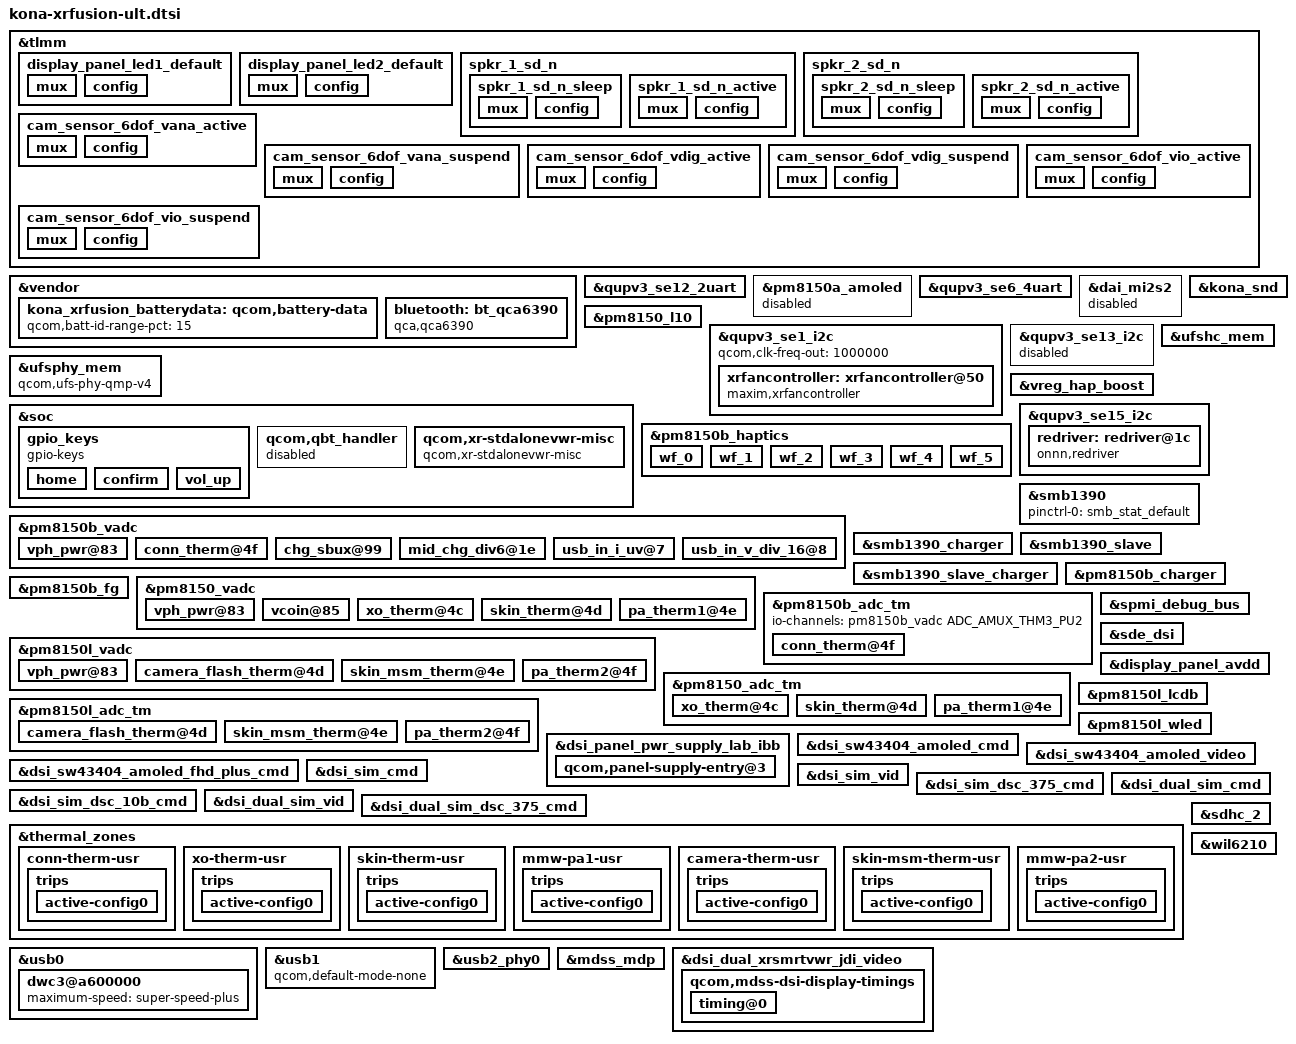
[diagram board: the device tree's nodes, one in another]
#include <dt-bindings/gpio/gpio.h>
#include "kona-pmic-overlay.dtsi"
#include "kona-sde-display.dtsi"
#include "kona-audio-overlay.dtsi"
#include "kona-thermal-overlay.dtsi"
#include "kona-xr-pinctrl-overlay.dtsi"
//#include "camera/kona-camera-sensor-xrfusion.dtsi"

&tlmm {
	display_panel_led1_default: display_panel_led1_default {
		mux {
			pins = "gpio144";
			function = "gpio";
		};

		config {
			pins = "gpio144";
			drive-strength = <8>;
			bias-disable = <0>;
			output-high;
		};
	};

	display_panel_led2_default: display_panel_led2_default {
		mux {
			pins = "gpio140";
			function = "gpio";
		};

		config {
			pins = "gpio140";
			drive-strength = <8>;
			bias-disable = <0>;
			output-high;
		};
	};

	spkr_1_sd_n {
		spkr_1_sd_n_sleep: spkr_1_sd_n_sleep {
			mux {
				pins = "gpio127";
				function = "gpio";
			};

			config {
				pins = "gpio127";
				drive-strength = <2>;   /* 2 mA */
				bias-pull-down;
				input-enable;
			};
		};

		spkr_1_sd_n_active: spkr_1_sd_n_active {
			mux {
				pins = "gpio127";
				function = "gpio";
			};

			config {
				pins = "gpio127";
				drive-strength = <16>;   /* 16 mA */
				bias-disable;
				output-high;
			};
		};
	};

	spkr_2_sd_n {
		spkr_2_sd_n_sleep: spkr_2_sd_n_sleep {
			mux {
				pins = "gpio129";
				function = "gpio";
			};

			config {
				pins = "gpio129";
				drive-strength = <2>;   /* 2 mA */
				bias-pull-down;
				input-enable;
			};
		};

		spkr_2_sd_n_active: spkr_2_sd_n_active {
			mux {
				pins = "gpio129";
				function = "gpio";
			};

			config {
				pins = "gpio129";
				drive-strength = <16>;   /* 16 mA */
				bias-disable;
				output-high;
			};
		};
	};

	cam_sensor_6dof_vana_active: cam_sensor_6dof_vana_active {
		/*  AVDD LDO */
		mux {
			pins = "gpio43";
			function = "gpio";
		};

		config {
			pins = "gpio43";
			bias-disable; /* No PULL */
			drive-strength = <2>; /* 2 MA */
		};
	};

	cam_sensor_6dof_vana_suspend: cam_sensor_6dof_vana_suspend {
		/*  AVDD LDO */
		mux {
			pins = "gpio43";
			function = "gpio";
		};

		config {
			pins = "gpio43";
			bias-pull-down; /* PULL DOWN */
			drive-strength = <2>; /* 2 MA */
		};
	};

	cam_sensor_6dof_vdig_active: cam_sensor_6dof_vdig_active {
		/*  VDIG LDO */
		mux {
			pins = "gpio42";
			function = "gpio";
		};

		config {
			pins = "gpio42";
			bias-disable; /* No PULL */
			drive-strength = <2>; /* 2 MA */
		};
	};

	cam_sensor_6dof_vdig_suspend: cam_sensor_6dof_vdig_suspend {
		/*  VDIG LDO */
		mux {
			pins = "gpio42";
			function = "gpio";
		};

		config {
			pins = "gpio42";
			bias-pull-down; /* PULL DOWN */
			drive-strength = <2>; /* 2 MA */
		};
	};

	cam_sensor_6dof_vio_active: cam_sensor_6dof_vio_active {
		/*  VIO LDO */
		mux {
			pins = "gpio41";
			function = "gpio";
		};

		config {
			pins = "gpio41";
			bias-disable; /* No PULL */
			drive-strength = <2>; /* 2 MA */
		};
	};

	cam_sensor_6dof_vio_suspend: cam_sensor_6dof_vio_suspend {
		/*  VIO LDO */
		mux {
			pins = "gpio41";
			function = "gpio";
		};

		config {
			pins = "gpio41";
			bias-pull-down; /* PULL DOWN */
			drive-strength = <2>; /* 2 MA */
		};
	};
};

&vendor {
	kona_xrfusion_batterydata: qcom,battery-data {
		qcom,batt-id-range-pct = <15>;
		#include "fg-gen4-batterydata-goertek-6100mah.dtsi"
	};
};

&qupv3_se12_2uart {
	status = "okay";
};

&pm8150a_amoled {
	status = "disabled";
};

&qupv3_se6_4uart {
	status = "ok";
};

&dai_mi2s2 {
	status = "disabled";
	qcom,msm-mi2s-tx-lines = <1>;
	pinctrl-names = "default", "sleep";
	pinctrl-0 = <&tert_mi2s_sck_active &tert_mi2s_ws_active
			&tert_mi2s_sd0_active>;
	pinctrl-1 = <&tert_mi2s_sck_sleep &tert_mi2s_ws_sleep
			&tert_mi2s_sd0_sleep>;
};

&kona_snd {
	qcom,model = "kona-xrfusion-ult-snd-card";
	qcom,mi2s-audio-intf = <0>;
	qcom,audio-routing =
		"AMIC1", "MIC BIAS1",
		"MIC BIAS1", "Analog Mic1",
		"AMIC2", "MIC BIAS2",
		"MIC BIAS2", "Analog Mic2",
		"AMIC3", "MIC BIAS3",
		"MIC BIAS3", "Analog Mic3",
		"AMIC4", "MIC BIAS4",
		"MIC BIAS4", "Analog Mic4",
		"AMIC5", "MIC BIAS5",
		"MIC BIAS5", "Analog Mic5",
		"AMIC6", "MIC BIAS6",
		"MIC BIAS6", "Analog Mic6",
		"DMIC0", "MIC BIAS1",
		"MIC BIAS1", "Digital Mic0",
		"DMIC1", "MIC BIAS1",
		"MIC BIAS1", "Digital Mic1",
		"DMIC2", "MIC BIAS1",
		"MIC BIAS1", "Digital Mic2",
		"DMIC3", "MIC BIAS1",
		"MIC BIAS1", "Digital Mic3",
		"DMIC4", "MIC BIAS3",
		"MIC BIAS3", "Digital Mic4",
		"DMIC5", "MIC BIAS4",
		"MIC BIAS4", "Digital Mic5",
		"DMIC6", "MIC BIAS3",
		"MIC BIAS3", "Digital Mic6",
		"DMIC7", "MIC BIAS3",
		"MIC BIAS3", "Digital Mic7",
		"IN1_HPHL", "HPHL_OUT",
		"IN2_HPHR", "HPHR_OUT",
		"IN3_AUX", "AUX_OUT",
		"TX SWR_ADC0", "ADC1_OUTPUT",
		"TX SWR_ADC1", "ADC2_OUTPUT",
		"TX SWR_ADC2", "ADC3_OUTPUT",
		"TX SWR_ADC3", "ADC4_OUTPUT",
		"TX SWR_DMIC0", "DMIC1_OUTPUT",
		"TX SWR_DMIC1", "DMIC2_OUTPUT",
		"TX SWR_DMIC2", "DMIC3_OUTPUT",
		"TX SWR_DMIC3", "DMIC4_OUTPUT",
		"TX SWR_DMIC4", "DMIC5_OUTPUT",
		"TX SWR_DMIC5", "DMIC6_OUTPUT",
		"TX SWR_DMIC6", "DMIC7_OUTPUT",
		"TX SWR_DMIC7", "DMIC8_OUTPUT",
		"WSA SRC0_INP", "SRC0",
		"WSA_TX DEC0_INP", "TX DEC0 MUX",
		"WSA_TX DEC1_INP", "TX DEC1 MUX",
		"RX_TX DEC0_INP", "TX DEC0 MUX",
		"RX_TX DEC1_INP", "TX DEC1 MUX",
		"RX_TX DEC2_INP", "TX DEC2 MUX",
		"RX_TX DEC3_INP", "TX DEC3 MUX",
		"SpkrRight IN", "WSA_SPK2 OUT",
		"VA_AIF1 CAP", "VA_SWR_CLK",
		"VA_AIF2 CAP", "VA_SWR_CLK",
		"VA_AIF3 CAP", "VA_SWR_CLK",
		"VA MIC BIAS3", "Digital Mic0",
		"VA MIC BIAS3", "Digital Mic1",
		"VA MIC BIAS1", "Digital Mic2",
		"VA MIC BIAS1", "Digital Mic3",
		"VA MIC BIAS4", "Digital Mic5",
		"VA DMIC0", "VA MIC BIAS3",
		"VA DMIC1", "VA MIC BIAS3",
		"VA DMIC2", "VA MIC BIAS1",
		"VA DMIC3", "VA MIC BIAS1",
		"VA DMIC5", "VA MIC BIAS4",
		"VA SWR_ADC1", "VA_SWR_CLK",
		"VA SWR_MIC0", "VA_SWR_CLK",
		"VA SWR_MIC1", "VA_SWR_CLK",
		"VA SWR_MIC2", "VA_SWR_CLK",
		"VA SWR_MIC3", "VA_SWR_CLK",
		"VA SWR_MIC4", "VA_SWR_CLK",
		"VA SWR_MIC5", "VA_SWR_CLK",
		"VA SWR_MIC6", "VA_SWR_CLK",
		"VA SWR_MIC7", "VA_SWR_CLK",
		"VA SWR_MIC0", "DMIC1_OUTPUT",
		"VA SWR_MIC1", "DMIC2_OUTPUT",
		"VA SWR_MIC2", "DMIC3_OUTPUT",
		"VA SWR_MIC3", "DMIC4_OUTPUT",
		"VA SWR_MIC4", "DMIC5_OUTPUT",
		"VA SWR_MIC5", "DMIC6_OUTPUT",
		"VA SWR_MIC6", "DMIC7_OUTPUT",
		"VA SWR_MIC7", "DMIC8_OUTPUT",
		"VA SWR_ADC1", "ADC2_OUTPUT";
		qcom,msm-mbhc-hphl-swh = <1>;
		qcom,msm-mbhc-gnd-swh = <1>;
		qcom,cdc-dmic01-gpios = <&cdc_dmic01_gpios>;
		qcom,cdc-dmic23-gpios = <&cdc_dmic23_gpios>;
		qcom,cdc-dmic45-gpios = <&cdc_dmic45_gpios>;
		asoc-codec  = <&stub_codec>, <&bolero>, <&ext_disp_audio_codec>;
		asoc-codec-names = "msm-stub-codec.1", "bolero_codec",
				"msm-ext-disp-audio-codec-rx";
		qcom,wsa-max-devs = <2>;
		qcom,wsa-devs = <&wsa881x_0211>, <&wsa881x_0212>,
		<&wsa881x_0213>, <&wsa881x_0214>;
		qcom,wsa-aux-dev-prefix = "SpkrLeft", "SpkrRight",
		"SpkrLeft", "SpkrRight";
		qcom,codec-max-aux-devs = <1>;
		qcom,codec-aux-devs = <&wcd938x_codec>;
		qcom,msm_audio_ssr_devs = <&audio_apr>, <&q6core>, <&lpi_tlmm>,
				<&bolero>;
};

&pm8150_l10 {
	regulator-max-microvolt = <3304000>;
	qcom,init-voltage = <3304000>;
};

&qupv3_se1_i2c {
	status = "ok";
	qcom,clk-freq-out = <1000000>;
	#address-cells = <1>;
	#size-cells = <0>;
	xrfancontroller: xrfancontroller@50 {
		compatible = "maxim,xrfancontroller";
		reg = <0x50>;
		qcom,fan-pwr-en = <&tlmm 38 0x00>;
		qcom,fan-pwr-bp = <&tlmm 39 0x00>;
	};
};

&qupv3_se13_i2c {
	#address-cells = <1>;
	#size-cells = <0>;

	status = "disabled";
};

&ufsphy_mem {
	compatible = "qcom,ufs-phy-qmp-v4";

	vdda-phy-supply = <&pm8150_l5>;
	vdda-phy-always-on;
	vdda-pll-supply = <&pm8150_l9>;
	vdda-phy-max-microamp = <89900>;
	vdda-pll-max-microamp = <18800>;

	status = "ok";
};

&ufshc_mem {
	vdd-hba-supply = <&ufs_phy_gdsc>;
	vdd-hba-fixed-regulator;
	vcc-supply = <&pm8150_l17>;
	vcc-voltage-level = <2504000 2950000>;
	vcc-low-voltage-sup;
	vccq-supply = <&pm8150_l6>;
	vccq2-supply = <&pm8150_s4>;
	vcc-max-microamp = <800000>;
	vccq-max-microamp = <800000>;
	vccq2-max-microamp = <800000>;

	qcom,vddp-ref-clk-supply = <&pm8150_l6>;
	qcom,vddp-ref-clk-max-microamp = <100>;
	qcom,vccq-parent-supply = <&pm8150a_s8>;
	qcom,vccq-parent-max-microamp = <210000>;

	status = "ok";
};

&soc {
	gpio_keys {
		compatible = "gpio-keys";
		label = "gpio-keys";

		pinctrl-names = "default";
		pinctrl-0 = <&key_vol_up_default
				&key_confirm_default
				&key_vol_up_default>;

		home {
			label = "home";
			gpios = <&pm8150_gpios 1 GPIO_ACTIVE_LOW>;
			linux,input-type = <1>;
			linux,code = <KEY_BACK>;
			gpio-key,wakeup;
			debounce-interval = <15>;
			linux,can-disable;
		};

		confirm {
			label = "confirm";
			gpios = <&pm8150_gpios 7 GPIO_ACTIVE_LOW>;
			linux,input-type = <1>;
			linux,code = <KEY_ENTER>;
			gpio-key,wakeup;
			debounce-interval = <15>;
			linux,can-disable;
		};

		vol_up {
			label = "volume_up";
			gpios = <&pm8150_gpios 6 GPIO_ACTIVE_LOW>;
			linux,input-type = <1>;
			linux,code = <KEY_VOLUMEUP>;
			gpio-key,wakeup;
			debounce-interval = <15>;
			linux,can-disable;
		};
	};

	qcom,qbt_handler {
		status = "disabled";
	};

	qcom,xr-stdalonevwr-misc {
		compatible = "qcom,xr-stdalonevwr-misc";
		/* IMU CLK Enable PM8150 GPIO 3 */
		pinctrl-names = "default", "sleep";
		pinctrl-0 = <&imu_clkin_default>;
		pinctrl-1 = <&imu_clkin_sleep>;
	};
};

&vreg_hap_boost {
	status = "ok";
};

&pm8150b_haptics {
	qcom,vmax-mv = <1697>;
	qcom,play-rate-us = <5882>;
	vdd-supply = <&vreg_hap_boost>;

	wf_0 {
		/* CLICK */
		qcom,wf-play-rate-us = <5882>;
		qcom,wf-vmax-mv = <1697>;
	};

	wf_1 {
		/* DOUBLE CLICK */
		qcom,wf-play-rate-us = <5882>;
		qcom,wf-vmax-mv = <1697>;
	};

	wf_2 {
		/* TICK */
		qcom,wf-play-rate-us = <5882>;
		qcom,wf-vmax-mv = <1697>;
	};

	wf_3 {
		/* THUD */
		qcom,wf-play-rate-us = <5882>;
		qcom,wf-vmax-mv = <1697>;
	};

	wf_4 {
		/* POP */
		qcom,wf-play-rate-us = <5882>;
		qcom,wf-vmax-mv = <1697>;
	};

	wf_5 {
		/* HEAVY CLICK */
		qcom,wf-play-rate-us = <5882>;
		qcom,wf-vmax-mv = <1697>;
	};
};

&pm8150b_vadc {
	#address-cells = <1>;
	#size-cells = <0>;

	vph_pwr@83 {
		reg = <ADC_VPH_PWR>;
		label = "vph_pwr";
		qcom,pre-scaling = <1 3>;
	};

	conn_therm@4f {
		reg = <ADC_AMUX_THM3_PU2>;
		label = "conn_therm";
		qcom,ratiometric;
		qcom,hw-settle-time = <200>;
		qcom,pre-scaling = <1 1>;
	};

	chg_sbux@99 {
		reg = <ADC_SBUx>;
		label = "chg_sbux";
		qcom,pre-scaling = <1 3>;
	};

	mid_chg_div6@1e {
		reg = <ADC_MID_CHG_DIV6>;
		label = "chg_mid";
		qcom,pre-scaling = <1 6>;
	};

	usb_in_i_uv@7 {
		reg = <ADC_USB_IN_I>;
		label = "usb_in_i_uv";
		qcom,pre-scaling = <1 1>;
	};

	usb_in_v_div_16@8 {
		reg = <ADC_USB_IN_V_16>;
		label = "usb_in_v_div_16";
		qcom,pre-scaling = <1 16>;
	};
};

&qupv3_se15_i2c {
	#address-cells = <1>;
	#size-cells = <0>;
	status = "ok";
	redriver: redriver@1c {
		compatible = "onnn,redriver";
		reg = <0x1c>;
		extcon = <&pm8150b_pdphy>, <&pm8150b_pdphy>;
		eq = /bits/ 8 <
				/* Parameters for USB */
				0x4 0x4 0x4 0x4
				/* Parameters for DP */
				0x6 0x4 0x4 0x6>;
		flat-gain = /bits/ 8 <
				/* Parameters for USB */
				0x3 0x1 0x1 0x3
				/* Parameters for DP */
				0x2 0x1 0x1 0x2>;
		output-comp = /bits/ 8 <
				/* Parameters for USB */
				0x3 0x3 0x3 0x3
				/* Parameters for DP */
				0x3 0x3 0x3 0x3>;
		loss-match = /bits/ 8 <
				/* Parameters for USB */
				0x1 0x3 0x3 0x1
				/* Parameters for DP */
				0x3 0x3 0x3 0x3>;
	};

	#include "smb1390.dtsi"
};

&smb1390 {
	pinctrl-names = "default";
	pinctrl-0 = <&smb_stat_default>;
	status = "ok";
};

&smb1390_charger {
	io-channels = <&pm8150b_vadc ADC_AMUX_THM2>;
	io-channel-names = "cp_die_temp";
	qcom,parallel-output-mode = <2>;
	status = "ok";
};

&smb1390_slave {
	status = "ok";
};

&smb1390_slave_charger {
	status = "ok";
};

&pm8150b_charger {
	status = "ok";
	qcom,sec-charger-config = <1>;
	qcom,auto-recharge-soc = <98>;
	io-channels = <&pm8150b_vadc ADC_MID_CHG_DIV6>,
		      <&pm8150b_vadc ADC_USB_IN_I>,
		      <&pm8150b_vadc ADC_SBUx>,
		      <&pm8150b_vadc ADC_VPH_PWR>,
		      <&pm8150b_vadc ADC_CHG_TEMP>;
	io-channel-names = "mid_voltage",
			   "usb_in_current",
			   "sbux_res",
			   "vph_voltage",
			   "chg_temp";
	qcom,battery-data = <&kona_xrfusion_batterydata>;
	qcom,sw-jeita-enable;
	qcom,wd-bark-time-secs = <16>;
	qcom,suspend-input-on-debug-batt;
	qcom,thermal-mitigation = <5325000 4500000 4000000 3500000 3000000
				2500000 2000000 1500000 1000000 500000>;
};

&pm8150b_fg {
	status = "ok";
	qcom,battery-data = <&kona_xrfusion_batterydata>;
	qcom,hold-soc-while-full;
	qcom,linearize-soc;
	qcom,five-pin-battery;
	qcom,cl-wt-enable;
	qcom,soc-scale-mode-en;
	/* ESR fast calibration */
	qcom,fg-esr-timer-chg-fast = <0 7>;
	qcom,fg-esr-timer-dischg-fast = <0 7>;
	qcom,fg-esr-timer-chg-slow = <0 96>;
	qcom,fg-esr-timer-dischg-slow = <0 96>;
	qcom,fg-esr-cal-soc-thresh = <26 230>;
	qcom,fg-esr-cal-temp-thresh = <10 40>;
};

&pm8150_vadc {
	#address-cells = <1>;
	#size-cells = <0>;

	vph_pwr@83 {
		reg = <ADC_VPH_PWR>;
		label = "vph_pwr";
		qcom,pre-scaling = <1 3>;
	};

	vcoin@85 {
		reg = <ADC_VCOIN>;
		label = "vcoin";
		qcom,pre-scaling = <1 3>;
	};

	xo_therm@4c {
		reg = <ADC_XO_THERM_PU2>;
		label = "xo_therm";
		qcom,ratiometric;
		qcom,hw-settle-time = <200>;
		qcom,pre-scaling = <1 1>;
	};

	skin_therm@4d {
		reg = <ADC_AMUX_THM1_PU2>;
		label = "skin_therm";
		qcom,ratiometric;
		qcom,hw-settle-time = <200>;
		qcom,pre-scaling = <1 1>;
	};

	pa_therm1@4e {
		reg = <ADC_AMUX_THM2_PU2>;
		label = "pa_therm1";
		qcom,ratiometric;
		qcom,hw-settle-time = <200>;
		qcom,pre-scaling = <1 1>;
	};
};

&pm8150l_vadc {
	#address-cells = <1>;
	#size-cells = <0>;

	vph_pwr@83 {
		reg = <ADC_VPH_PWR>;
		label = "vph_pwr";
		qcom,pre-scaling = <1 3>;
	};

	camera_flash_therm@4d {
		reg = <ADC_AMUX_THM1_PU2>;
		label = "camera_flash_therm";
		qcom,ratiometric;
		qcom,hw-settle-time = <200>;
		qcom,pre-scaling = <1 1>;
	};

	skin_msm_therm@4e {
		reg = <ADC_AMUX_THM2_PU2>;
		label = "skin_msm_therm";
		qcom,ratiometric;
		qcom,hw-settle-time = <200>;
		qcom,pre-scaling = <1 1>;
	};

	pa_therm2@4f {
		reg = <ADC_AMUX_THM3_PU2>;
		label = "pa_therm2";
		qcom,ratiometric;
		qcom,hw-settle-time = <200>;
		qcom,pre-scaling = <1 1>;
	};
};

&pm8150b_adc_tm {
	#address-cells = <1>;
	#size-cells = <0>;

	io-channels = <&pm8150b_vadc ADC_AMUX_THM3_PU2>;

	conn_therm@4f {
		reg = <ADC_AMUX_THM3_PU2>;
		qcom,ratiometric;
		qcom,hw-settle-time = <200>;
	};
};

&pm8150_adc_tm {
	#address-cells = <1>;
	#size-cells = <0>;

	io-channels = <&pm8150_vadc ADC_XO_THERM_PU2>,
			<&pm8150_vadc ADC_AMUX_THM1_PU2>,
			<&pm8150_vadc ADC_AMUX_THM2_PU2>;

	xo_therm@4c {
		reg = <ADC_XO_THERM_PU2>;
		qcom,ratiometric;
		qcom,hw-settle-time = <200>;
	};

	skin_therm@4d {
		reg = <ADC_AMUX_THM1_PU2>;
		qcom,ratiometric;
		qcom,hw-settle-time = <200>;
	};

	pa_therm1@4e {
		reg = <ADC_AMUX_THM2_PU2>;
		qcom,ratiometric;
		qcom,hw-settle-time = <200>;
	};
};

&pm8150l_adc_tm {
	#address-cells = <1>;
	#size-cells = <0>;

	camera_flash_therm@4d {
		reg = <ADC_AMUX_THM1_PU2>;
		qcom,ratiometric;
		qcom,hw-settle-time = <200>;
	};

	skin_msm_therm@4e {
		reg = <ADC_AMUX_THM2_PU2>;
		qcom,ratiometric;
		qcom,hw-settle-time = <200>;
	};

	pa_therm2@4f {
		reg = <ADC_AMUX_THM3_PU2>;
		qcom,ratiometric;
		qcom,hw-settle-time = <200>;
	};
};

&spmi_debug_bus {
	status = "ok";
};

&sde_dsi {
	avdd-supply = <&display_panel_avdd>;
	lab-supply = <&lcdb_ldo_vreg>;
	ibb-supply = <&lcdb_ncp_vreg>;
	qcom,dsi-default-panel = <&dsi_dual_xrsmrtvwr_jdi_video>;
};

&display_panel_avdd {
	display_panel_led1_gpio = <&tlmm 144 0>;
	display_panel_led2_gpio = <&tlmm 140 0>;
	enable-active-high;
	regulator-boot-on;
	pinctrl-names = "default";
	pinctrl-0 = <&display_panel_led1_default
	&display_panel_led2_default>;
};

&dsi_panel_pwr_supply_lab_ibb {
	qcom,panel-supply-entry@3 {
		reg = <1>;
		qcom,supply-name = "avdd";
		qcom,supply-min-voltage = <4600000>;
		qcom,supply-max-voltage = <6000000>;
		qcom,supply-enable-load = <100000>;
		qcom,supply-disable-load = <100>;
	};
};

&pm8150l_lcdb {
	status = "ok";
};

&pm8150l_wled {
	status = "ok";
};

&dsi_sw43404_amoled_cmd {
	qcom,panel-supply-entries = <&dsi_panel_pwr_supply>;
	qcom,mdss-dsi-bl-pmic-control-type = "bl_ctrl_dcs";
	qcom,mdss-dsi-bl-min-level = <1>;
	qcom,mdss-dsi-bl-max-level = <1023>;
	qcom,mdss-brightness-max-level = <255>;
	qcom,platform-te-gpio = <&tlmm 66 0>;
	qcom,platform-reset-gpio = <&tlmm 75 0>;
	qcom,mdss-dsi-panel-test-pin = <&tlmm 46 0>;
};

&dsi_sw43404_amoled_video {
	qcom,panel-supply-entries = <&dsi_panel_pwr_supply>;
	qcom,mdss-dsi-bl-pmic-control-type = "bl_ctrl_dcs";
	qcom,mdss-dsi-bl-min-level = <1>;
	qcom,mdss-dsi-bl-max-level = <1023>;
	qcom,mdss-brightness-max-level = <255>;
	qcom,platform-reset-gpio = <&tlmm 75 0>;
	qcom,mdss-dsi-panel-test-pin = <&tlmm 46 0>;
};

&dsi_sw43404_amoled_fhd_plus_cmd {
	qcom,panel-supply-entries = <&dsi_panel_pwr_supply>;
	qcom,mdss-dsi-bl-pmic-control-type = "bl_ctrl_dcs";
	qcom,mdss-dsi-bl-min-level = <1>;
	qcom,mdss-dsi-bl-max-level = <1023>;
	qcom,mdss-brightness-max-level = <255>;
	qcom,platform-te-gpio = <&tlmm 66 0>;
	qcom,platform-reset-gpio = <&tlmm 75 0>;
	qcom,mdss-dsi-panel-test-pin = <&tlmm 46 0>;
};

&dsi_sim_cmd {
	qcom,panel-supply-entries = <&dsi_panel_pwr_supply>;
	qcom,mdss-dsi-bl-pmic-control-type = "bl_ctrl_dcs";
	qcom,platform-reset-gpio = <&tlmm 75 0>;
};

&dsi_sim_vid {
	qcom,panel-supply-entries = <&dsi_panel_pwr_supply>;
	qcom,mdss-dsi-bl-pmic-control-type = "bl_ctrl_dcs";
	qcom,platform-reset-gpio = <&tlmm 75 0>;
};

&dsi_sim_dsc_375_cmd {
	qcom,panel-supply-entries = <&dsi_panel_pwr_supply>;
	qcom,mdss-dsi-bl-pmic-control-type = "bl_ctrl_dcs";
	qcom,platform-reset-gpio = <&tlmm 75 0>;
};

&dsi_sim_dsc_10b_cmd {
	qcom,panel-supply-entries = <&dsi_panel_pwr_supply>;
	qcom,mdss-dsi-bl-pmic-control-type = "bl_ctrl_dcs";
	qcom,platform-reset-gpio = <&tlmm 75 0>;
};

&dsi_dual_sim_cmd {
	qcom,panel-supply-entries = <&dsi_panel_pwr_supply>;
	qcom,mdss-dsi-bl-pmic-control-type = "bl_ctrl_dcs";
	qcom,platform-reset-gpio = <&tlmm 75 0>;
};

&dsi_dual_sim_vid {
	qcom,panel-supply-entries = <&dsi_panel_pwr_supply>;
	qcom,mdss-dsi-bl-pmic-control-type = "bl_ctrl_dcs";
	qcom,platform-reset-gpio = <&tlmm 75 0>;
};

&dsi_dual_sim_dsc_375_cmd {
	qcom,panel-supply-entries = <&dsi_panel_pwr_supply>;
	qcom,mdss-dsi-bl-pmic-control-type = "bl_ctrl_dcs";
	qcom,platform-reset-gpio = <&tlmm 75 0>;
};

&thermal_zones {
	conn-therm-usr {
		polling-delay-passive = <0>;
		polling-delay = <0>;
		thermal-governor = "user_space";
		thermal-sensors = <&pm8150b_adc_tm ADC_AMUX_THM3_PU2>;
		trips {
			active-config0 {
				temperature = <125000>;
				hysteresis = <1000>;
				type = "passive";
			};
		};
	};

	xo-therm-usr {
		polling-delay-passive = <0>;
		polling-delay = <0>;
		thermal-governor = "user_space";
		thermal-sensors = <&pm8150_adc_tm ADC_XO_THERM_PU2>;
		trips {
			active-config0 {
				temperature = <125000>;
				hysteresis = <1000>;
				type = "passive";
			};
		};
	};

	skin-therm-usr {
		polling-delay-passive = <0>;
		polling-delay = <0>;
		thermal-governor = "user_space";
		thermal-sensors = <&pm8150_adc_tm ADC_AMUX_THM1_PU2>;
		trips {
			active-config0 {
				temperature = <125000>;
				hysteresis = <1000>;
				type = "passive";
			};
		};
	};

	mmw-pa1-usr {
		polling-delay-passive = <0>;
		polling-delay = <0>;
		thermal-governor = "user_space";
		thermal-sensors = <&pm8150_adc_tm ADC_AMUX_THM2_PU2>;
		trips {
			active-config0 {
				temperature = <125000>;
				hysteresis = <1000>;
				type = "passive";
			};
		};
	};

	camera-therm-usr {
		polling-delay-passive = <0>;
		polling-delay = <0>;
		thermal-governor = "user_space";
		thermal-sensors = <&pm8150l_adc_tm ADC_AMUX_THM1_PU2>;
		trips {
			active-config0 {
				temperature = <125000>;
				hysteresis = <1000>;
				type = "passive";
			};
		};
	};

	skin-msm-therm-usr {
		polling-delay-passive = <0>;
		polling-delay = <0>;
		thermal-governor = "user_space";
		thermal-sensors = <&pm8150l_adc_tm ADC_AMUX_THM2_PU2>;
		trips {
			active-config0 {
				temperature = <125000>;
				hysteresis = <1000>;
				type = "passive";
			};
		};
	};

	mmw-pa2-usr {
		polling-delay-passive = <0>;
		polling-delay = <0>;
		thermal-governor = "user_space";
		thermal-sensors = <&pm8150l_adc_tm ADC_AMUX_THM3_PU2>;
		trips {
			active-config0 {
				temperature = <125000>;
				hysteresis = <1000>;
				type = "passive";
			};
		};
	};
};

&sdhc_2 {
	vdd-supply = <&pm8150a_l9>;
	qcom,vdd-voltage-level = <2950000 2960000>;
	qcom,vdd-current-level = <200 800000>;

	vdd-io-supply = <&pm8150a_l6>;
	qcom,vdd-io-voltage-level = <1808000 2960000>;
	qcom,vdd-io-current-level = <200 22000>;

	pinctrl-names = "active", "sleep";
	pinctrl-0 = <&sdc2_clk_on  &sdc2_cmd_on &sdc2_data_on &storage_cd>;
	pinctrl-1 = <&sdc2_clk_off &sdc2_cmd_off &sdc2_data_off &storage_cd>;

	cd-gpios = <&tlmm 77 GPIO_ACTIVE_HIGH>; /* Morpheus has to be HIGH */

	status = "ok";
};

&vendor {
	bluetooth: bt_qca6390 {
		compatible = "qca,qca6390";
		pinctrl-names = "default";
		pinctrl-0 = <&bt_en_sleep>;
		qca,bt-reset-gpio = <&tlmm 21 0>; /* BT_EN */
		qca,bt-vdd-aon-supply = <&pm8150_s6>;
		qca,bt-vdd-dig-supply = <&pm8009_s2>;
		qca,bt-vdd-rfa1-supply = <&pm8150_s5>;
		qca,bt-vdd-rfa2-supply = <&pm8150a_s8>;
		qca,bt-vdd-asd-supply = <&pm8150_l16>;

		qca,bt-vdd-aon-voltage-level = <950000 950000>;
		qca,bt-vdd-dig-voltage-level = <950000 952000>;
		qca,bt-vdd-rfa1-voltage-level = <1900000 1900000>;
		qca,bt-vdd-rfa2-voltage-level = <1350000 1350000>;
		qca,bt-vdd-asd-voltage-level = <3024000 3304000>;

		qca,bt-vdd-asd-current-level = <10000>;
	};
};

&usb0 {
	dwc3@a600000 {
		maximum-speed = "super-speed-plus";
	};
};

&usb1 {
	qcom,default-mode-none;
};

&wil6210 {
	status = "ok";
};

&usb2_phy0 {
	qcom,param-override-seq =
		<0xc7 0x6c
		0x0f 0x70
		0x03 0x74>;
};

&mdss_mdp {
	qcom,sde-mixer-display-pref = "primary", "primary", "primary",
					"primary", "none", "none";
};

&dsi_dual_xrsmrtvwr_jdi_video {
	qcom,panel-supply-entries = <&dsi_panel_pwr_supply_lab_ibb>;
	qcom,mdss-dsi-bl-pmic-control-type = "bl_ctrl_external";
	qcom,mdss-dsi-bl-min-level = <1>;
	qcom,mdss-dsi-bl-max-level = <4095>;
	qcom,mdss-brightness-max-level = <255>;
	qcom,platform-reset-gpio = <&tlmm 75 0>;
	qcom,platform-te-gpio = <&tlmm 66 0>;

	qcom,platform-bklight-en-gpio = <&tlmm 133 0>;
	qcom,5v-boost-gpio = <&tlmm 134 0>;
	/delete-property/ qcom,platform-en-gpio;

	qcom,mdss-dsi-panel-status-command = [06 01 00 01 00 00 01 0a];
	qcom,mdss-dsi-panel-status-command-state = "dsi_hs_mode";
	qcom,mdss-dsi-panel-status-value = <0x9c>;
	qcom,mdss-dsi-panel-on-check-value = <0x9c>;
	qcom,mdss-dsi-panel-status-read-length = <1>;
	qcom,dsi-select-clocks = "mux_byte_clk0", "mux_pixel_clk0";
	qcom,dsi-supported-dfps-list = <90 75 60>;
	qcom,mdss-dsi-pan-enable-dynamic-fps;
	qcom,mdss-dsi-pan-fps-update = "dfps_immediate_porch_mode_vfp";
	qcom,mdss-dsi-min-refresh-rate = <60>;
	qcom,mdss-dsi-max-refresh-rate = <90>;
	qcom,mdss-dsi-display-timings {
		timing@0 {
			qcom,mdss-dsi-panel-width = <2160>;
			qcom,mdss-dsi-panel-height = <2160>;
			qcom,mdss-dsi-h-front-porch = <20>;
			qcom,mdss-dsi-h-back-porch = <20>;
			qcom,mdss-dsi-h-pulse-width = <20>;
			qcom,mdss-dsi-h-sync-skew = <0>;
			qcom,mdss-dsi-v-back-porch = <20>;
			qcom,mdss-dsi-v-front-porch = <936>;
			qcom,mdss-dsi-v-pulse-width = <4>;
			qcom,mdss-dsi-panel-framerate = <90>;
			qcom,mdss-dsi-on-command = [
				29 01 00 00 00 00 02 B0 04
				29 01 00 00 00 00 02 D6 00
				29 01 00 00 00 00 0A B6 30 6B 80 06 33
					8A 00 1A 7A
				29 01 00 00 00 00 05 B7 54 00 00 00
				29 01 00 00 00 00 05 B9 10 00 01 38
				29 01 00 00 00 00 09 C0 51 86 64 00 08
					70 07 00
				29 01 00 00 00 00 02 F1 1E
				29 01 00 00 00 00 11 C6 70 08 D0 02 21
					6F 08 5A 00 00 00 00 00 00 00 00
				29 01 00 00 00 00 02 CD 00
				29 01 00 00 00 00 08 CF 8B 00 80 46 61
					00 8B
				29 01 00 00 00 00 06 EC 02 96 00 00 00
				39 01 00 00 00 00 02 03 01
				39 01 00 00 00 00 03 44 00 00
				39 01 00 00 00 00 02 35 00
				39 01 00 00 00 00 02 36 00
				39 01 00 00 00 00 02 3A 77
				05 01 00 00 02 00 02 29 00
				05 01 00 00 80 00 02 11 00
				29 01 00 00 00 00 02 D6 80
				29 01 00 00 00 00 02 B0 03
				];
			qcom,mdss-dsi-off-command = [
				05 01 00 00 32 00 02 28 00
				05 01 00 00 32 00 02 34 00
				05 01 00 00 78 00 02 10 00
				];
			qcom,mdss-dsi-on-command-state = "dsi_lp_mode";
			qcom,mdss-dsi-off-command-state = "dsi_hs_mode";
			qcom,mdss-dsi-h-sync-pulse = <0>;
			qcom,compression-mode = "dsc";
			qcom,mdss-dsc-slice-height = <8>;
			qcom,mdss-dsc-slice-width = <540>;
			qcom,mdss-dsc-slice-per-pkt = <2>;
			qcom,mdss-dsc-bit-per-component = <8>;
			qcom,mdss-dsc-bit-per-pixel = <8>;
			qcom,mdss-dsc-block-prediction-enable;
			qcom,mdss-dsi-panel-phy-timings =  [00 17 05 05 20 1F
						06 06 03 02 04 00 13 15];
			qcom,display-topology = <4 4 2>,
						<1 0 2>;
			qcom,default-topology-index = <0>;

		};
	};
};
